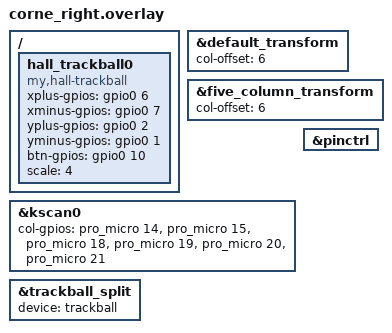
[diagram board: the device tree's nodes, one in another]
/*
 * Copyright (c) 2020 Pete Johanson
 *
 * SPDX-License-Identifier: MIT
 */

#include "corne.dtsi"

&default_transform {
    col-offset = <6>;
};

&five_column_transform {
    col-offset = <6>;
};

&kscan0 {
    col-gpios
        = <&pro_micro 14 GPIO_ACTIVE_HIGH>
        , <&pro_micro 15 GPIO_ACTIVE_HIGH>
        , <&pro_micro 18 GPIO_ACTIVE_HIGH>
        , <&pro_micro 19 GPIO_ACTIVE_HIGH>
        , <&pro_micro 20 GPIO_ACTIVE_HIGH>
        , <&pro_micro 21 GPIO_ACTIVE_HIGH>
        ;
};

/ {
  hall_trackball0: hall_trackball0 {
    compatible = "my,hall-trackball";
    status = "okay";
    xplus-gpios  = <&gpio0 6 (GPIO_PULL_UP | GPIO_ACTIVE_HIGH)>;
    xminus-gpios = <&gpio0 7 (GPIO_PULL_UP | GPIO_ACTIVE_HIGH)>;
    yplus-gpios  = <&gpio0 2 (GPIO_PULL_UP | GPIO_ACTIVE_HIGH)>;
    yminus-gpios = <&gpio0 1 (GPIO_PULL_UP | GPIO_ACTIVE_HIGH)>;
    btn-gpios    = <&gpio0 10 (GPIO_PULL_UP | GPIO_ACTIVE_HIGH)>;
    scale = <4>;
  };
};

&trackball_split {
  device = <&hall_trackball0>;
};

/* This is the important part: tell the split proxy what device to forward */
&trackball_split {
    device = <&trackball>;

    /* Optional: if you need axis fixes before sending to central, add processors here */
    /* input-processors = <(INPUT_TRANSFORM_X_INVERT)>; */
    };


// Enable ZMK mouse emulation listener
&pinctrl {
    // any pinctrl definitions if needed
};

// vim: filetype=dts fdm=marker:
